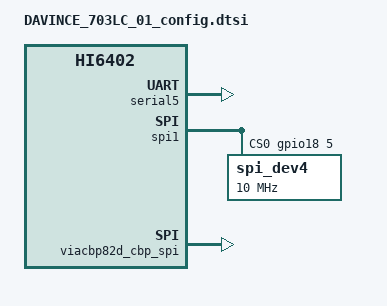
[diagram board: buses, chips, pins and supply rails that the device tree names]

/**
 * Huawei Ltd.
 * PhosphorV660
 */


/include/ "fastboot.dtsi"
/include/ "DAVINCE_703L_01_config.dtsi"
/include/ "DAVINCE_703LC_01_pin.dtsi"
/include/ "DAVINCE_703LC_01_hi6402_pin.dtsi"
/include/ "DAVINCE_703LC_01_modem_pin.dtsi"
///include/ "DAVINCE_703LC_01_charger.dtsi"
///include/ "DAVINCE_703LC_01_pmic.dtsi"
///include/ "DAVINCE_703LC_01_gpio_logic.dtsi"
/include/ "huawei_ext_modem.dtsi"

/ {
	hisi,boardid = <1 1 2 2 >;
	hisi,boardname = "DAVINCE_703LC_01";
	hisi,modem_id = <0x3E9E6880>;
	hisi,hardware_version="STENDAV703LCAPV0001";

	amba {
		serial5: uart@fdf05000 {
			pinctrl-names = "default", "idle";
			pinctrl-0 = <>;
			pinctrl-1 = <>;
			dmas;
			dma-names;
			//pinctrl-0 = <&gpio068_pmx_func &gpio069_pmx_func &gpio070_pmx_func &gpio068_cfg_func
			//	     &gpio069_cfg_func &gpio070_cfg_func &gpio071_cfg_func>;
			//pinctrl-1 = <&gpio068_pmx_idle &gpio069_pmx_idle &gpio070_pmx_idle &gpio068_cfg_idle
			//	     &gpio069_cfg_idle &gpio070_cfg_idle &gpio071_cfg_idle>;
			reset-controller-reg = <0x078 0x07c 0x080 15>;
			status = "ok";
		};

		spi1: spi@fdf08000 {
				status = "ok";
				pinctrl-names = "default", "idle";
				pinctrl-0 = <&gpio146_pmx_func &gpio147_pmx_func &gpio148_pmx_func &gpio149_pmx_func
					     &gpio146_cfg_func &gpio147_cfg_func &gpio148_cfg_func &gpio149_cfg_func>;
				pinctrl-1 = <&gpio146_pmx_idle &gpio147_pmx_idle &gpio148_pmx_idle &gpio149_pmx_idle
					     &gpio146_cfg_idle &gpio147_cfg_idle &gpio148_cfg_idle &gpio149_cfg_idle>;

				num-cs = <1>;
				#address-cells = <1>;
				#size-cells = <0>;
				cs-gpios = <&gpio18 5 0>;
				spi_dev4: spi_dev4@4 {
						compatible = "spi_dev4";
						spi-max-frequency = <10000000>;
						reg = <0>;
						pl022,com-mode = <2>;
						pl022,interface = <0>;
						pl022,rx-level-trig = <3>;
						pl022,tx-level-trig = <3>;
						pl022,ctrl-len = <7>;
						pl022,wait-state = <0>;
						pl022,duplex = <0>;
						pl022,slave-tx-disable = <0>;
				};
		};
	};

    viacbp82d_power:viacbp82d_power {
        via_backup = <&gpio4 1 0>;			// ap notify via produce ramdump 33
        status = "ok";
    };
    viacbp82d_cbp_spi:viacbp82d_cbp_spi {
        via_ap_abort_cp = <&gpio11 6 0>;	// ap abort cp,           182
        status = "ok";
    };
    rnic_adapter:rnic_adapter {
        status = "ok";
    };
};

